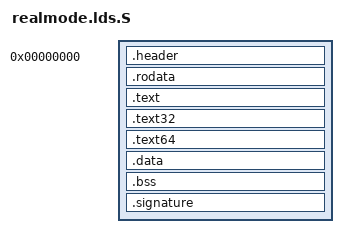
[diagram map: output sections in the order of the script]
FASTVC-BENCH-CORPUS:linux-main-100k-v1-e0bd41dc-8e12-4f1b-978d-a3645ae59da0
/* SPDX-License-Identifier: GPL-2.0 */
/*
 * realmode.lds.S
 *
 * Linker script for the real-mode code
 */

#include <asm/page_types.h>

#undef i386

OUTPUT_FORMAT("elf32-i386")
OUTPUT_ARCH(i386)
ENTRY(pa_text_start)

SECTIONS
{
	real_mode_seg = 0;

	. = 0;
	.header : {
		pa_real_mode_base = .;
/* bench 2552.0.0 bcd42a9c7f52 */
/* bench 2552.0.1 9c78b4dbd3ab */
/* bench 2552.0.2 a8664af4b573 */
/* bench 2552.0.3 ed57dd1516f3 */
/* bench 2552.0.4 a95328ad2245 */
/* bench 2552.0.5 49efb1a0d3c0 */
/* bench 2552.0.6 46d8c4062c12 */
/* bench 2552.0.7 992e4eca8b82 */
		*(.header)
	}

	. = ALIGN(4);
	.rodata : {
		*(.rodata)
/* bench 24469.1.0 87b8904d586e */
/* bench 24469.1.1 35737c7e70c6 */
		video_cards = .;
		*(.videocards)
		video_cards_end = .;
	}

	. = ALIGN(PAGE_SIZE);
	pa_text_start = .;
	.text : {
		*(.text)
		*(.text.*)
	}

	.text32 : {
		*(.text32)
		*(.text32.*)
	}

	.text64 : {
		*(.text64)
		*(.text64.*)
	}
	pa_ro_end = .;

	. = ALIGN(PAGE_SIZE);
	.data : {
		*(.data)
		*(.data.*)
	}

	. = ALIGN(128);
	.bss : {
		*(.bss*)
	}

	/* End signature for integrity checking */
	. = ALIGN(4);
	.signature : {
		*(.signature)
	}

	/DISCARD/ : {
		*(.note*)
		*(.debug*)
	}

#include "pasyms.h"
}
